# LargeDummyDevice register map
File version: 1.0
Registers are 32-bit, read-write, no defined reset value unless marked. A register's access mark holds for its fields unless they carry their own. Offsets are from the block's base; [hi:lo] are bit positions.

## PERIPHERAL_20
Base 0x40013000
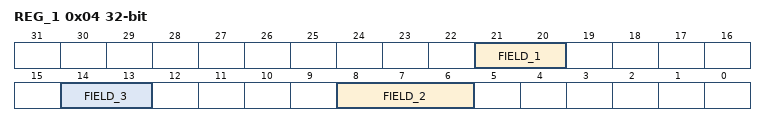
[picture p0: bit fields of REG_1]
0x04 REG_1 — Register 1
  [33:31] FIELD_5, [33:31] FIELD_6, [33:30] FIELD_16, [32:29] FIELD_1, [29] FIELD_18, [29:28] FIELD_24, [28:25] FIELD_8, [23:20] FIELD_10, [23:20] FIELD_15, [21:19] FIELD_2, [21:19] FIELD_3, [19] FIELD_12, [22:19] FIELD_21, [18] FIELD_25, [19:18] FIELD_27, [18:17] FIELD_23, [17:16] FIELD_13, [19:15] FIELD_7, [13:11] FIELD_20, [13:9] FIELD_17, [9] FIELD_19, [12:9] FIELD_22, [8] FIELD_4, [4] FIELD_14, [4:3] FIELD_9, [4:2] FIELD_26, [3:1] FIELD_11
0x08 REG_2 — Register 2
  [27:25] FIELD_2, [27:24] FIELD_7, [23:21] FIELD_8, [23:20] FIELD_5, [17:16] FIELD_3, [17:13] FIELD_9, [14:10] FIELD_6, [12:8] FIELD_4, [9:7] FIELD_1
0x0C REG_3 — Register 3
  [32:30] FIELD_22, [29] FIELD_16, [30:29] FIELD_21, [27] FIELD_14, [27:25] FIELD_9, [24] FIELD_5, [23:22] FIELD_17, [24:21] FIELD_12, [15] FIELD_6, [13] FIELD_19, [15:12] FIELD_3, [16:12] FIELD_15, [12] FIELD_18, [12:10] FIELD_4, [9:8] FIELD_13, [8:4] FIELD_1, [5:4] FIELD_7, [7:4] FIELD_20, [3] FIELD_2, [3:2] FIELD_8, [5:2] FIELD_10, [1] FIELD_11
0x10 REG_4 — Register 4
  [30:28] FIELD_13, [27:23] FIELD_16, [26:23] FIELD_22, [23] FIELD_24, [23] FIELD_26, [26:22] FIELD_17, [24:20] FIELD_3, [22:20] FIELD_21, [22:19] FIELD_10, [22:19] FIELD_18, [21:19] FIELD_28, [21:18] FIELD_5, [18:16] FIELD_2, [20:16] FIELD_9, [18:16] FIELD_15, [15] FIELD_8, [17:14] FIELD_4, [13:12] FIELD_12, [12:11] FIELD_30, [11:8] FIELD_20, [11:7] FIELD_23, [6] FIELD_27, [6:4] FIELD_7, [7:4] FIELD_29, [6:3] FIELD_1, [4:3] FIELD_11, [3] FIELD_19, [5:2] FIELD_25, [3:1] FIELD_14, [4:0] FIELD_6
0x14 REG_5 — Register 5
  [31:30] FIELD_8, [31:29] FIELD_7, [29:28] FIELD_1, [22:21] FIELD_2, [23:19] FIELD_9, [14] FIELD_3, [11:8] FIELD_5, [4:2] FIELD_4, [5:2] FIELD_6
0x18 REG_6 — Register 6
  [34:31] FIELD_1, [30:28] FIELD_6, [30:26] FIELD_22, [28:25] FIELD_9, [24] FIELD_10, [25:22] FIELD_3, [26:22] FIELD_12, [25:22] FIELD_21, [22:21] FIELD_17, [23:19] FIELD_18, [18:17] FIELD_16, [17:16] FIELD_2, [18:16] FIELD_20, [13:10] FIELD_11, [13:9] FIELD_4, [10:8] FIELD_8, [11:7] FIELD_7, [5] FIELD_5, [5] FIELD_14, [8:5] FIELD_19, [7:3] FIELD_15, [0] FIELD_13
0x1C REG_7 — Register 7
  [27:25] FIELD_5, [21:18] FIELD_3, [18:17] FIELD_1, [19:15] FIELD_4, [8:6] FIELD_7, [6:5] FIELD_6, [3:2] FIELD_2
0x20 REG_8 — Register 8
  [33:30] FIELD_1
0x24 REG_9 — Register 9
  [33:29] FIELD_5, [30:29] FIELD_7, [31:29] FIELD_8, [29] FIELD_11, [28] FIELD_17, [28:27] FIELD_10, [31:27] FIELD_20, [27] FIELD_24, [26] FIELD_16, [27:24] FIELD_3, [22:21] FIELD_12, [22:20] FIELD_23, [21:19] FIELD_15, [19:18] FIELD_19, [17:16] FIELD_2, [18:16] FIELD_18, [16:14] FIELD_25, [16:12] FIELD_21, [10:9] FIELD_13, [10:7] FIELD_6, [6] FIELD_9, [3:2] FIELD_14, [1] FIELD_4, [2:0] FIELD_1, [2:0] FIELD_22

## PERIPHERAL_23
Base 0x40016000
0x04 REG_1 — Register 1
  [32:31] FIELD_19, [32:30] FIELD_7, [34:30] FIELD_22, [30:29] FIELD_6, [33:29] FIELD_14, [29] FIELD_18, [29] FIELD_29, [29:28] FIELD_2, [28:27] FIELD_27, [27:25] FIELD_11, [25:22] FIELD_8, [22] FIELD_21, [21:20] FIELD_9, [21:20] FIELD_12, [21:17] FIELD_5, [20:17] FIELD_15, [16:14] FIELD_10, [18:14] FIELD_16, [14:11] FIELD_1, [12:10] FIELD_3, [8] FIELD_4, [10:8] FIELD_28, [8:7] FIELD_17, [8:4] FIELD_20, [5:4] FIELD_25, [5:2] FIELD_26, [2:1] FIELD_24, [0] FIELD_13, [0] FIELD_23
0x08 REG_2 — Register 2
  [6:5] FIELD_1
0x0C REG_3 — Register 3
  [29:27] FIELD_11, [23] FIELD_4, [22] FIELD_2, [26:22] FIELD_8, [24:20] FIELD_10, [11:9] FIELD_9, [7:6] FIELD_6, [4:3] FIELD_5, [7:3] FIELD_7, [1] FIELD_3, [3:0] FIELD_1

## PERIPHERAL_26
Base 0x40019000
0x04 REG_1 — Register 1
  [21:20] FIELD_1, [14:13] FIELD_3, [8:6] FIELD_2
0x08 REG_2 — Register 2
  [32:31] FIELD_9, [30:28] FIELD_2, [31:28] FIELD_10, [29:28] FIELD_13, [23:20] FIELD_15, [19:15] FIELD_14, [14:13] FIELD_1, [14:13] FIELD_16, [10] FIELD_3, [10] FIELD_7, [12:9] FIELD_11, [10:7] FIELD_5, [7:5] FIELD_4, [4] FIELD_8, [7:4] FIELD_12, [4:0] FIELD_6
0x0C REG_3 — Register 3
  [33:31] FIELD_10, [33:29] FIELD_4, [32:29] FIELD_28, [28:26] FIELD_25, [27:24] FIELD_31, [26:23] FIELD_7, [23] FIELD_24, [26:23] FIELD_29, [24:23] FIELD_30, [23:22] FIELD_21, [24:21] FIELD_27, [20] FIELD_5, [23:20] FIELD_14, [22:20] FIELD_18, [19:18] FIELD_8, [21:17] FIELD_3, [16] FIELD_12, [16:14] FIELD_6, [14] FIELD_23, [13] FIELD_11, [12:9] FIELD_1, [13:9] FIELD_9, [11:9] FIELD_20, [10:8] FIELD_13, [9:8] FIELD_26, [8:7] FIELD_19, [7] FIELD_22, [6:5] FIELD_15, [8:5] FIELD_16, [8:4] FIELD_2, [5:3] FIELD_17
